# ESP32S31_RADIO register map
Vendor: Espressif; Series: ESP32-S31; File version: 3.52
Registers are 32-bit, read-write, no defined reset value unless marked. A register's access mark holds for its fields unless they carry their own. Offsets are from the block's base; [hi:lo] are bit positions; {n}, {i} and the like mark numbered series.

## WIFI_MAC_HE_TB_STATISTICS — Hardware counters read by the complete hal_he_get_rx_trigger_cnt, hal_he_get_tb_times_cnt and hal_he_get_tb_qosnull_cnt leaves. These counters distinguish Trigger reception from actual trigger-based transmission and appended QoS Null responses. An ordinary controlled HE SU AP produced no Trigger frames, so all three remained zero during sustained HE DCM A-MPDU traffic.
Base 0x201043A0
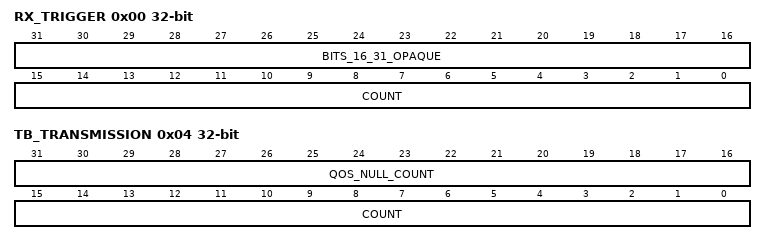
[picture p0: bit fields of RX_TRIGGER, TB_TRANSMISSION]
0x00 RX_TRIGGER ro — Project-assigned name. Complete hal_he_get_rx_trigger_cnt returns the low sixteen bits.
  [31:16] BITS_16_31_OPAQUE — Opaque: meaning not established.
  [15:0] COUNT — Project-assigned name.
0x04 TB_TRANSMISSION ro — Project-assigned name. Complete hal_he_get_tb_times_cnt returns the low sixteen bits; complete hal_he_get_tb_qosnull_cnt returns the high sixteen bits.
  [31:16] QOS_NULL_COUNT — Project-assigned name.
  [15:0] COUNT — Project-assigned name.

## WIFI_MAC_HE_TB_DIAGNOSTICS — Four read-only hardware result words decoded by complete dbg_read_axtb_diag and its four complete getter leaves. The names come from the pinned blob's own format strings; no field meaning is inferred from reset images. All four words remained zero when the controlled AP sent no Trigger frames.
Base 0x201044F4
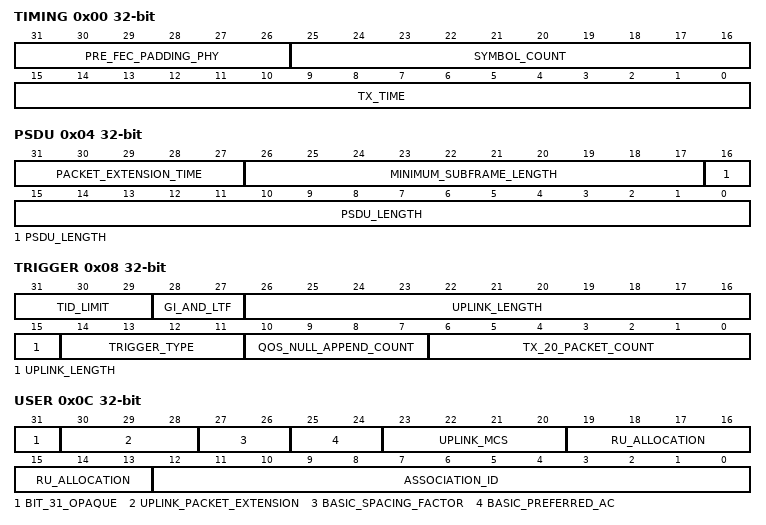
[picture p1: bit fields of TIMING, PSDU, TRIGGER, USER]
0x00 TIMING ro — Project-assigned name. WDEVAXTBDIAG0.
  [31:26] PRE_FEC_PADDING_PHY — Project-assigned name.
  [25:16] SYMBOL_COUNT — Project-assigned name.
  [15:0] TX_TIME — Project-assigned name.
0x04 PSDU ro — Project-assigned name. WDEVAXTBDIAG1.
  [31:27] PACKET_EXTENSION_TIME — Project-assigned name.
  [26:17] MINIMUM_SUBFRAME_LENGTH — Project-assigned name.
  [16:0] PSDU_LENGTH — Project-assigned name.
0x08 TRIGGER ro — Project-assigned name. WDEVAXTBDIAG2.
  [31:29] TID_LIMIT — Project-assigned name.
  [28:27] GI_AND_LTF — Project-assigned name.
  [26:15] UPLINK_LENGTH — Project-assigned name.
  [14:11] TRIGGER_TYPE — Project-assigned name.
  [10:7] QOS_NULL_APPEND_COUNT — Project-assigned name.
  [6:0] TX_20_PACKET_COUNT — Project-assigned name.
0x0C USER ro — Project-assigned name. WDEVAXTBDIAG3.
  [31] BIT_31_OPAQUE — Opaque: meaning not established.
  [30:28] UPLINK_PACKET_EXTENSION — Project-assigned name.
  [27:26] BASIC_SPACING_FACTOR — Project-assigned name.
  [25:24] BASIC_PREFERRED_AC — Project-assigned name.
  [23:20] UPLINK_MCS — Project-assigned name.
  [19:13] RU_ALLOCATION — Project-assigned name.
  [12:0] ASSOCIATION_ID — Project-assigned name.

## WIFI_MAC_HE_MU_EDCA_TIMER — Four MU-EDCA timer words decoded by complete dbg_read_muedca_timer. Durations are reported by the blob in eight-TU units. Complete blob and ROM libpp[hal_mac_tx.o]::mac_tx_set_tb and rom[]::mac_tx_set_tb set ENABLE in the timer selected by the logical TX queue before publishing the Trigger queue configuration. After open HE association and TID0 AddBA, all four ordinary-SU baseline words had ENABLE=0, TIMER/CURRENT/AIFS=0 and REACHED=1; that pre-port baseline AP emitted no Trigger frame.
Base 0x20104DBC
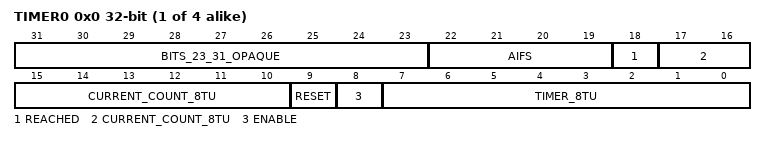
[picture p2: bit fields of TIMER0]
{0x0+4i} TIMER{i} (i=0..3) — Project-assigned name. WDEVMUEDCA_TIMER[0-3].
  [31:23] BITS_23_31_OPAQUE — Opaque: meaning not established.
  [22:19] AIFS — Project-assigned name.
  [18] REACHED — Project-assigned name.
  [17:10] CURRENT_COUNT_8TU — Project-assigned name.
  [9] RESET — Project-assigned name.
  [8] ENABLE — Project-assigned name.
  [7:0] TIMER_8TU — Project-assigned name.

## WIFI_MAC_BEAMFORMING_FEEDBACK_TEST — Test-only beamforming-feedback selector written by complete esp_test_bf_set_feedback. The write transforms and selector branches are exact; the public meaning of selector values zero through sixteen is not present in the archive, so only bounded functional names are assigned.
Base 0x20104E00
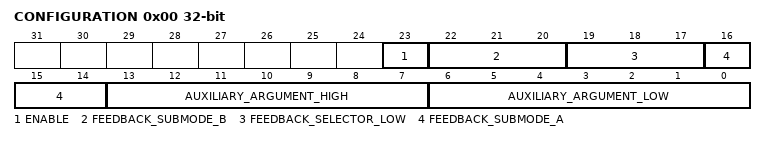
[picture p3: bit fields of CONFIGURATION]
0x00 CONFIGURATION — Project-assigned name. A zero enable argument clears ENABLE only. A nonzero argument first sets ENABLE, clears FEEDBACK_SUBMODE_B, replaces both seven-bit auxiliary arguments, then applies selector-dependent updates to the remaining submode fields. Selector sixteen replaces the complete word with ENABLE plus FEEDBACK_SUBMODE_B value one.
  [23] ENABLE — Project-assigned name. A nonzero enable argument sets this bit; zero clears it.
  [22:20] FEEDBACK_SUBMODE_B — Project-assigned name. Three-bit selector-dependent field. The common enabled prefix clears it; selectors twelve and sixteen publish one.
  [19:17] FEEDBACK_SELECTOR_LOW — Project-assigned name. For selectors zero through seven this field receives the three-bit selector. The higher selector classes update it only partially or clear it.
  [16:14] FEEDBACK_SUBMODE_A — Project-assigned name. Three-bit selector-dependent field. Complete branches publish one for selector thirteen and five for selector fourteen.
  [13:7] AUXILIARY_ARGUMENT_HIGH — Project-assigned name. High seven-bit argument passed as esp_test_bf_set_feedback argument three.
  [6:0] AUXILIARY_ARGUMENT_LOW — Project-assigned name. Low seven-bit argument passed as esp_test_bf_set_feedback argument two.
